AUTOSAR XML (schema 00051)
package /ComponentTypes
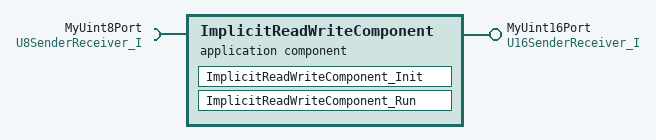
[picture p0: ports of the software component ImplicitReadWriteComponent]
  application sw component type ImplicitReadWriteComponent
    require port MyUint8Port: nonqueued-receiver-com-spec{data-element=Value, init-value=255}, required-interface=U8SenderReceiver_I
    provide port MyUint16Port: nonqueued-sender-com-spec{data-element=Value, init-value=65535}, provided-interface=U16SenderReceiver_I
    behavior ImplicitReadWriteComponent_InternalBehavior
      runnable ImplicitReadWriteComponent_Init
      runnable ImplicitReadWriteComponent_Run
        data-read-access:
          access READ_MyUint8Port_Value: accessed-variable=MyUint8Port.Value
        data-write-access:
          access WRITE_MyUint16Port_Value: accessed-variable=MyUint16Port.Value
  swc implementation ImplicitReadWriteComponent_Implementation: behavior=ImplicitReadWriteComponent_InternalBehavior
